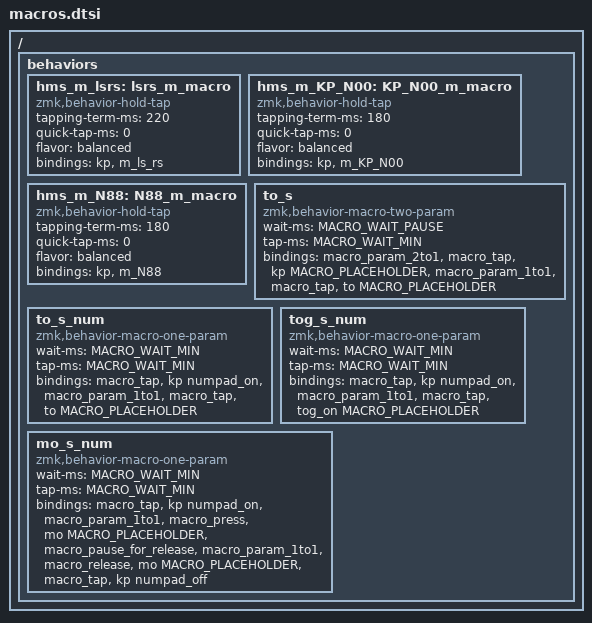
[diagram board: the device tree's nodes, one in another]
#define MACRO_WAIT_DEFAULT        2
#define MACRO_TAP_DEFAULT         10
#define MACRO_WAIT_MIN            0
#define MACRO_WAIT_CHORD         40
#define MACRO_WAIT_PAUSE          7
#define MACRO_WAIT_ALT_LONG      65
#define MACRO_WAIT_ALT_SHORT     40
#define MACRO_TAP_9_16           18
#define MACRO_WAIT_LAS           15
#define MACRO_WAIT_SPACE_DELAY       50
#define MACRO_WAIT_SPACE_DELAY_ROLL  65
#define MACRO_WAIT_SPACE_DELAY_LDW   90
#define MACRO_WAIT_SPACE_PRIOR       120
#define MACRO_WAIT_SPACE_ROLL        120
#define MACRO_WAIT_SPACE_L_PRIOR      55

#define ZMK_MACRO_(name,...) \
	name: name { \
		compatible = "zmk,behavior-macro"; \
		#binding-cells = <0>; \
		wait-ms = <MACRO_WAIT_DEFAULT>; \
		tap-ms = <MACRO_TAP_DEFAULT>; \
		__VA_ARGS__ \
	};

/ { behaviors {
	/* Hold-tap wrappers that invoke a macro on hold */
	hms_m_lsrs: lsrs_m_macro {
		compatible = "zmk,behavior-hold-tap";
		#binding-cells = <2>;
		tapping-term-ms = <220>;
		quick-tap-ms = <0>;
		flavor = "balanced";
		bindings = <&kp>, <&m_ls_rs>;
	};

	ZMK_MACRO_(m_ls_rs,
		wait-ms = <MACRO_WAIT_CHORD>;
		bindings = <&macro_press &kp LSHFT>,
			<&macro_tap &kp RSHFT>,
			<&macro_release &kp LSHFT>;
	)

	hms_m_KP_N00: KP_N00_m_macro {
		compatible = "zmk,behavior-hold-tap";
		#binding-cells = <2>;
		tapping-term-ms = <180>;
		quick-tap-ms = <0>;
		flavor = "balanced";
		bindings = <&kp>, <&m_KP_N00>;
	};

	ZMK_MACRO_(m_KP_N00,
		bindings = <&kp KP_N0 &kp KP_N0>;
	)

	hms_m_N88: N88_m_macro {
		compatible = "zmk,behavior-hold-tap";
		#binding-cells = <2>;
		tapping-term-ms = <180>;
		quick-tap-ms = <0>;
		flavor = "balanced";
		bindings = <&kp>, <&m_N88>;
	};

	ZMK_MACRO_(m_N88,
		bindings = <&macro_press &kp LSHFT>,
			<&macro_tap &kp N8 &kp N8>,
			<&macro_release &kp LSHFT>;
	)

	/* Numpad / Excel helpers */
	ZMK_MACRO_(m_sum,
		bindings = <&kp S &kp M &kp E &kp MINUS>;
	)

	ZMK_MACRO_(m_paste_transp,
		wait-ms = <MACRO_WAIT_CHORD>;
		bindings = <&kp RC(LA(FSLH)) &kp LA(FSLH) &kp K &kp ENTER>;
	)

	ZMK_MACRO_(m_calc,
		bindings = <&macro_press &kp RGUI &kp RSHFT>,
			<&macro_tap &kp N3>,
			<&macro_release &kp RGUI &kp RSHFT>;
	)

	ZMK_MACRO_(m_las_n2,
		bindings = <&kp LALT>,
			<&macro_wait_time MACRO_WAIT_LAS>,
			<&kp LS(N2)>;
	)

	ZMK_MACRO_(m_las_n3,
		bindings = <&kp LALT>,
			<&macro_wait_time MACRO_WAIT_LAS>,
			<&kp LS(N3)>;
	)

	ZMK_MACRO_(m_las_n7,
		bindings = <&kp LALT>,
			<&macro_wait_time MACRO_WAIT_LAS>,
			<&kp LS(N7)>;
	)

	/* Term rolls — see docs/term-layout.md (ak_SPACE). */
	ZMK_MACRO_(m_space_delayed,
		wait-ms = <MACRO_WAIT_MIN>;
		tap-ms = <MACRO_WAIT_MIN>;
		bindings = <&macro_wait_time MACRO_WAIT_SPACE_DELAY &kp SPACE>;
	)

	ZMK_MACRO_(m_space_delayed_roll,
		wait-ms = <MACRO_WAIT_MIN>;
		tap-ms = <MACRO_WAIT_MIN>;
		bindings = <&macro_wait_time MACRO_WAIT_SPACE_DELAY_ROLL &kp SPACE>;
	)

	ZMK_MACRO_(m_space_delayed_ldw_l,
		wait-ms = <MACRO_WAIT_MIN>;
		tap-ms = <MACRO_WAIT_MIN>;
		bindings = <&macro_wait_time MACRO_WAIT_SPACE_DELAY_LDW &kp SPACE>;
	)

	/* Layer + F17/F18 signaling */
	ZMK_MACRO_(m_to_steno,
		bindings = <&to STENO &kp steno_on>;
	)

	ZMK_MACRO_(m_from_steno,
		bindings = <&to DEFAULT_HD &kp steno_off>;
	)

	ZMK_MACRO_(m_to_steno_np_off,
		bindings = <&to STENO &kp steno_on &kp numpad_off>;
	)

	ZMK_MACRO_(m_from_steno_np_off,
		bindings = <&to DEFAULT_HD &kp steno_off &kp numpad_off>;
	)

	/* Steno word macros (Plover HID press/release) */
	ZMK_MACRO_(m_pren,
		bindings = <&macro_press &plv PLV_PL &plv PLV_RL &plv PLV_E &plv PLV_PR &plv PLV_BR>,
			<&macro_release &plv PLV_PL &plv PLV_RL &plv PLV_E &plv PLV_PR &plv PLV_BR>;
	)

	ZMK_MACRO_(m_pren_s,
		bindings = <&macro_press &plv PLV_PL &plv PLV_RL &plv PLV_E &plv PLV_PR &plv PLV_BR &plv PLV_ST>,
			<&macro_release &plv PLV_PL &plv PLV_RL &plv PLV_E &plv PLV_PR &plv PLV_BR &plv PLV_ST>;
	)

	/* Email / name tap-dance targets */
	ZMK_MACRO_(m_email_w,
		bindings = <&kp G &kp SEMI &kp M &kp K &kp A &kp GRAVE &kp J>,
			<&kp LS(I)>,
			<&kp T &kp J &kp S &kp J &kp GRAVE &kp V &kp SEMI>,
			<&kp W &kp C &kp COMMA &kp B &kp J &kp C>,
			<&kp I &kp V &kp COMMA &kp E>;
	)

	ZMK_MACRO_(m_email_g,
		bindings = <&kp G &kp SEMI &kp M &kp K &kp A &kp GRAVE &kp J &kp DOT>,
			<&kp LS(I)>,
			<&kp W &kp E &kp J &kp L &kp C>,
			<&kp I &kp V &kp COMMA &kp E>;
	)

	ZMK_MACRO_(m_email_w_old,
		bindings = <&kp G &kp SEMI &kp M &kp K &kp A &kp GRAVE &kp J>,
			<&kp LS(I)>,
			<&kp T &kp J &kp S &kp J &kp GRAVE &kp V &kp SEMI &kp J>,
			<&kp F &kp FSLH &kp L &kp S &kp COMMA &kp A &kp S>,
			<&kp I &kp V &kp COMMA &kp E>;
	)

	ZMK_MACRO_(m_email_ph,
		bindings = <&kp G &kp SEMI>,
			<&kp LS(I)>,
			<&kp T &kp J &kp S &kp J &kp GRAVE &kp V &kp SEMI>,
			<&kp W &kp C &kp COMMA &kp B &kp J &kp C>,
			<&kp I &kp V &kp COMMA &kp E>;
	)

	ZMK_MACRO_(m_phuerta,
		bindings = <&kp G &kp SEMI &kp M &kp K &kp A &kp GRAVE &kp J>;
	)

	ZMK_MACRO_(m_ph,
		bindings = <&kp LS(G) &kp K &kp F &kp A &kp COMMA>,
			<&kp SPACE>,
			<&kp LS(SEMI) &kp M &kp K &kp A &kp GRAVE &kp J>;
	)

	ZMK_MACRO_(m_pihy,
		bindings = <&kp LS(G) &kp K &kp F &kp A &kp COMMA>,
			<&kp SPACE>,
			<&kp LS(L) &kp I>,
			<&kp SPACE>,
			<&kp LS(SEMI) &kp M &kp K &kp A &kp GRAVE &kp J>,
			<&kp SPACE>,
			<&kp LS(DOT) &kp M &kp E &kp SEMI &kp J>;
	)

	ZMK_MACRO_(m_9_16,
		tap-ms = <MACRO_TAP_9_16>;
		bindings = <&macro_wait_time MACRO_WAIT_ALT_LONG>,
			<&kp LALT>,
			<&macro_wait_time MACRO_WAIT_ALT_SHORT>,
			<&kp Q &kp J &kp SEMI &kp KP_N9 &kp TAB &kp KP_N1 &kp KP_N6 &kp ENTER &kp ESC>;
	)

	ZMK_MACRO_(m_9_16_steno,
		tap-ms = <MACRO_TAP_9_16>;
		bindings = <&macro_wait_time MACRO_WAIT_ALT_LONG>,
			<&kp LALT>,
			<&macro_wait_time MACRO_WAIT_ALT_SHORT>,
			<&kp Q &kp J &kp SEMI &kp LS(N1) &kp TAB &kp LS(N3) &kp LS(N6) &kp ENTER &kp ESC>;
	)

	/* Parametric layer + signal macros (F17/F18) */
	to_s: to_s {
		compatible = "zmk,behavior-macro-two-param";
		wait-ms = <MACRO_WAIT_PAUSE>;
		tap-ms = <MACRO_WAIT_MIN>;
		#binding-cells = <2>;
		bindings = <&macro_param_2to1>
			, <&macro_tap &kp MACRO_PLACEHOLDER>
			, <&macro_param_1to1>
			, <&macro_tap &to MACRO_PLACEHOLDER>;
	};

	to_s_num: to_s_num {
		compatible = "zmk,behavior-macro-one-param";
		wait-ms = <MACRO_WAIT_MIN>;
		tap-ms = <MACRO_WAIT_MIN>;
		#binding-cells = <1>;
		bindings = <&macro_tap &kp numpad_on>
			, <&macro_param_1to1>
			, <&macro_tap &to MACRO_PLACEHOLDER>;
	};

	tog_s_num: tog_s_num {
		compatible = "zmk,behavior-macro-one-param";
		wait-ms = <MACRO_WAIT_MIN>;
		tap-ms = <MACRO_WAIT_MIN>;
		#binding-cells = <1>;
		bindings = <&macro_tap &kp numpad_on>
			, <&macro_param_1to1>
			, <&macro_tap &tog_on MACRO_PLACEHOLDER>;
	};

	mo_s_num: mo_s_num {
		compatible = "zmk,behavior-macro-one-param";
		wait-ms = <MACRO_WAIT_MIN>;
		tap-ms = <MACRO_WAIT_MIN>;
		#binding-cells = <1>;
		bindings = <&macro_tap &kp numpad_on>
			, <&macro_param_1to1>
			, <&macro_press &mo MACRO_PLACEHOLDER>
			, <&macro_pause_for_release>
			, <&macro_param_1to1>
			, <&macro_release &mo MACRO_PLACEHOLDER>
			, <&macro_tap &kp numpad_off>;
	};
}; };
